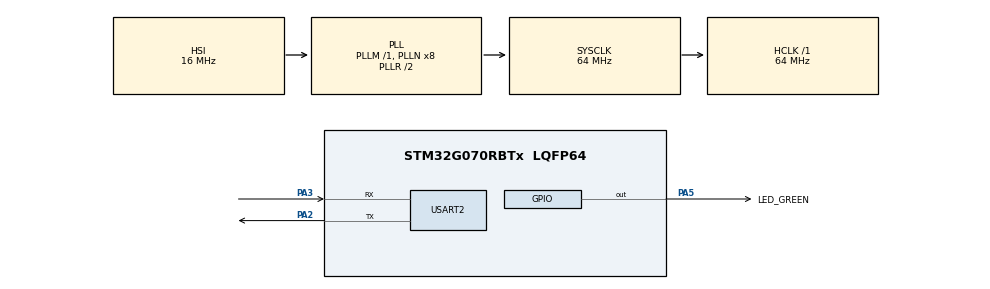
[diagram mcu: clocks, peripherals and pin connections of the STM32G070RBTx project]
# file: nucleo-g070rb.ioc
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Dma.Request0=USART2_TX
Dma.USART2_TX.0.Direction=DMA_MEMORY_TO_PERIPH
Dma.USART2_TX.0.EventEnable=DISABLE
Dma.USART2_TX.0.Instance=DMA1_Channel1
Dma.USART2_TX.0.MemDataAlignment=DMA_MDATAALIGN_BYTE
Dma.USART2_TX.0.MemInc=DMA_MINC_ENABLE
Dma.USART2_TX.0.Mode=DMA_NORMAL
Dma.USART2_TX.0.PeriphDataAlignment=DMA_PDATAALIGN_BYTE
Dma.USART2_TX.0.PeriphInc=DMA_PINC_DISABLE
Dma.USART2_TX.0.Polarity=HAL_DMAMUX_REQ_GEN_RISING
Dma.USART2_TX.0.Priority=DMA_PRIORITY_LOW
Dma.USART2_TX.0.RequestNumber=1
Dma.USART2_TX.0.SignalID=NONE
Dma.USART2_TX.0.SyncEnable=DISABLE
Dma.USART2_TX.0.SyncPolarity=HAL_DMAMUX_SYNC_NO_EVENT
Dma.USART2_TX.0.SyncRequestNumber=1
Dma.USART2_TX.0.SyncSignalID=NONE
FREERTOS.BinarySemaphores01=elog_lock,Dynamic,NULL;elog_async,Dynamic,NULL;elog_dma_lock,Dynamic,NULL
FREERTOS.Tasks01=defaultTask,24,256,StartDefaultTask,Default,NULL,Static,defaultTaskBuffer,defaultTaskControlBlock;elog,8,512,elog_entry,As external,NULL,Static,elogBuffer,elogControlBlock
FREERTOS.configUSE_NEWLIB_REENTRANT=1
Mcu.Family=STM32G0
Mcu.Name=STM32G070RBTx
Mcu.Package=LQFP64
NVIC.DMA1_Channel1_IRQn=true\:3\:0\:false\:false\:true\:true\:false\:true\:true
NVIC.TIM1_BRK_UP_TRG_COM_IRQn=true\:3\:0\:false\:false\:true\:false\:false\:true\:true
NVIC.TimeBase=TIM1_BRK_UP_TRG_COM_IRQn
NVIC.TimeBaseIP=TIM1
NVIC.USART2_IRQn=true\:3\:0\:false\:false\:true\:true\:true\:true\:true
PA13.GPIO_Label=TMS
PA13.Mode=Serial_Wire
PA13.Signal=SYS_SWDIO
PA14-BOOT0.GPIO_Label=TCK
PA14-BOOT0.Mode=Serial_Wire
PA14-BOOT0.Signal=SYS_SWCLK
PA2.GPIO_PuPd=GPIO_PULLUP
PA2.Mode=Asynchronous
PA2.Signal=USART2_TX
PA3.GPIO_PuPd=GPIO_PULLUP
PA3.Mode=Asynchronous
PA3.Signal=USART2_RX
PA5.GPIO_Label=LED_GREEN
PA5.GPIO_Speed=GPIO_SPEED_FREQ_HIGH
PA5.Signal=GPIO_Output
PC13.Mode=SYS_WakeUp1
PC13.Signal=SYS_WKUP2
PC14-OSC32_IN\ (PC14).Mode=LSE-External-Oscillator
PC14-OSC32_IN\ (PC14).Signal=RCC_OSC32_IN
PC15-OSC32_OUT\ (PC15).Mode=LSE-External-Oscillator
PC15-OSC32_OUT\ (PC15).Signal=RCC_OSC32_OUT
PF0-OSC_IN\ (PF0).GPIO_Label=MCO
PF0-OSC_IN\ (PF0).Mode=HSE-External-Clock-Source
PF0-OSC_IN\ (PF0).Signal=RCC_OSC_IN
ProjectManager.HeapSize=0x200
ProjectManager.StackSize=0x400
ProjectManager.TargetToolchain=STM32CubeIDE
RCC.ADCFreq_Value=64000000
RCC.AHBFreq_Value=64000000
RCC.CortexFreq_Value=64000000
RCC.EXTERNAL_CLOCK_VALUE=12288000
RCC.HCLKFreq_Value=64000000
RCC.HSE_VALUE=8000000
RCC.HSI_VALUE=16000000
RCC.SYSCLKFreq_VALUE=64000000
RCC.SYSCLKSource=RCC_SYSCLKSOURCE_PLLCLK
RCC.VCOOutputFreq_Value=128000000
USART2.VirtualMode-Asynchronous=VM_ASYNC
USART2.WordLength=WORDLENGTH_8B
VP_FREERTOS_VS_CMSIS_V2.Mode=CMSIS_V2
VP_SYS_VS_tim1.Mode=TIM1
board=NUCLEO-G070RB

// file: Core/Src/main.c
/* USER CODE BEGIN Header */
/**
  ******************************************************************************
  * @file           : main.c
  * @brief          : Main program body
  ******************************************************************************
  * @attention
  *
  * Copyright (c) 2022 STMicroelectronics.
  * All rights reserved.
  *
  * This software is licensed under terms that can be found in the LICENSE file
  * in the root directory of this software component.
  * If no LICENSE file comes with this software, it is provided AS-IS.
  *
  ******************************************************************************
  */
/* USER CODE END Header */
#include "main.h"
#include "cmsis_os.h"
#include "dma.h"
#include "usart.h"
#include "gpio.h"

/* USER CODE BEGIN Includes */
#include "elog.h"
/* USER CODE END Includes */

void SystemClock_Config(void);
void MX_FREERTOS_Init(void);

/* USER CODE BEGIN 0 */
void HAL_UART_TxCpltCallback(UART_HandleTypeDef *huart) {
    if (huart->Instance == huart2.Instance) {
        extern osSemaphoreId_t elog_dma_lockHandle;
        osSemaphoreRelease(elog_dma_lockHandle);
    }
}
/* USER CODE END 0 */

int main(void)
{

  /* MCU Configuration--------------------------------------------------------*/

  /* Reset of all peripherals, Initializes the Flash interface and the Systick. */
  HAL_Init();

  /* Configure the system clock */
  SystemClock_Config();

  /* Initialize all configured peripherals */
  MX_GPIO_Init();
  MX_DMA_Init();
  MX_USART2_UART_Init();
  /* USER CODE BEGIN 2 */
  elog_init();

  elog_set_fmt(ELOG_LVL_ASSERT, ELOG_FMT_ALL & ~ELOG_FMT_P_INFO);
  elog_set_fmt(ELOG_LVL_ERROR, ELOG_FMT_LVL | ELOG_FMT_TAG | ELOG_FMT_TIME);
  elog_set_fmt(ELOG_LVL_WARN, ELOG_FMT_LVL | ELOG_FMT_TAG | ELOG_FMT_TIME);
  elog_set_fmt(ELOG_LVL_INFO, ELOG_FMT_LVL | ELOG_FMT_TAG | ELOG_FMT_TIME);
  elog_set_fmt(ELOG_LVL_DEBUG, ELOG_FMT_ALL & ~(ELOG_FMT_FUNC | ELOG_FMT_P_INFO));
  elog_set_fmt(ELOG_LVL_VERBOSE, ELOG_FMT_ALL & ~(ELOG_FMT_FUNC | ELOG_FMT_P_INFO));

  elog_start();
  /* USER CODE END 2 */

  /* Init scheduler */
  osKernelInitialize();  /* Call init function for freertos objects (in freertos.c) */
  MX_FREERTOS_Init();

  /* Start scheduler */
  osKernelStart();

  /* We should never get here as control is now taken by the scheduler */
  /* Infinite loop */
  while (1)
  {

  }
}

void SystemClock_Config(void)
{
  RCC_OscInitTypeDef RCC_OscInitStruct = {0};
  RCC_ClkInitTypeDef RCC_ClkInitStruct = {0};

  /** Configure the main internal regulator output voltage
  */
  HAL_PWREx_ControlVoltageScaling(PWR_REGULATOR_VOLTAGE_SCALE1);

  /** Initializes the RCC Oscillators according to the specified parameters
  * in the RCC_OscInitTypeDef structure.
  */
  RCC_OscInitStruct.OscillatorType = RCC_OSCILLATORTYPE_HSI;
  RCC_OscInitStruct.HSIState = RCC_HSI_ON;
  RCC_OscInitStruct.HSIDiv = RCC_HSI_DIV1;
  RCC_OscInitStruct.HSICalibrationValue = RCC_HSICALIBRATION_DEFAULT;
  RCC_OscInitStruct.PLL.PLLState = RCC_PLL_ON;
  RCC_OscInitStruct.PLL.PLLSource = RCC_PLLSOURCE_HSI;
  RCC_OscInitStruct.PLL.PLLM = RCC_PLLM_DIV1;
  RCC_OscInitStruct.PLL.PLLN = 8;
  RCC_OscInitStruct.PLL.PLLP = RCC_PLLP_DIV2;
  RCC_OscInitStruct.PLL.PLLR = RCC_PLLR_DIV2;
  if (HAL_RCC_OscConfig(&RCC_OscInitStruct) != HAL_OK)
  {
    Error_Handler();
  }

  /** Initializes the CPU, AHB and APB buses clocks
  */
  RCC_ClkInitStruct.ClockType = RCC_CLOCKTYPE_HCLK|RCC_CLOCKTYPE_SYSCLK
                              |RCC_CLOCKTYPE_PCLK1;
  RCC_ClkInitStruct.SYSCLKSource = RCC_SYSCLKSOURCE_PLLCLK;
  RCC_ClkInitStruct.AHBCLKDivider = RCC_SYSCLK_DIV1;
  RCC_ClkInitStruct.APB1CLKDivider = RCC_HCLK_DIV1;

  if (HAL_RCC_ClockConfig(&RCC_ClkInitStruct, FLASH_LATENCY_2) != HAL_OK)
  {
    Error_Handler();
  }
}

void HAL_TIM_PeriodElapsedCallback(TIM_HandleTypeDef *htim)
{
  if (htim->Instance == TIM1) {
    HAL_IncTick();
  }
}

void Error_Handler(void)
{
  __disable_irq();
  while (1)
  {
  }
}

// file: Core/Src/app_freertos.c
/* USER CODE BEGIN Header */
/**
  ******************************************************************************
  * File Name          : app_freertos.c
  * Description        : Code for freertos applications
  ******************************************************************************
  * @attention
  *
  * Copyright (c) 2022 STMicroelectronics.
  * All rights reserved.
  *
  * This software is licensed under terms that can be found in the LICENSE file
  * in the root directory of this software component.
  * If no LICENSE file comes with this software, it is provided AS-IS.
  *
  ******************************************************************************
  */
/* USER CODE END Header */

#include "FreeRTOS.h"
#include "task.h"
#include "main.h"
#include "cmsis_os.h"

/* USER CODE BEGIN Includes */
#include "elog.h"
/* USER CODE END Includes */

typedef StaticTask_t osStaticThreadDef_t;

/* Definitions for defaultTask */
osThreadId_t defaultTaskHandle;
uint32_t defaultTaskBuffer[ 256 ];
osStaticThreadDef_t defaultTaskControlBlock;
const osThreadAttr_t defaultTask_attributes = {
  .name = "defaultTask",
  .stack_mem = &defaultTaskBuffer[0],
  .stack_size = sizeof(defaultTaskBuffer),
  .cb_mem = &defaultTaskControlBlock,
  .cb_size = sizeof(defaultTaskControlBlock),
  .priority = (osPriority_t) osPriorityNormal,
};
/* Definitions for elog */
osThreadId_t elogHandle;
uint32_t elogBuffer[ 512 ];
osStaticThreadDef_t elogControlBlock;
const osThreadAttr_t elog_attributes = {
  .name = "elog",
  .stack_mem = &elogBuffer[0],
  .stack_size = sizeof(elogBuffer),
  .cb_mem = &elogControlBlock,
  .cb_size = sizeof(elogControlBlock),
  .priority = (osPriority_t) osPriorityLow,
};
/* Definitions for elog_lock */
osSemaphoreId_t elog_lockHandle;
const osSemaphoreAttr_t elog_lock_attributes = {
  .name = "elog_lock"
};
/* Definitions for elog_async */
osSemaphoreId_t elog_asyncHandle;
const osSemaphoreAttr_t elog_async_attributes = {
  .name = "elog_async"
};
/* Definitions for elog_dma_lock */
osSemaphoreId_t elog_dma_lockHandle;
const osSemaphoreAttr_t elog_dma_lock_attributes = {
  .name = "elog_dma_lock"
};

void StartDefaultTask(void *argument);
extern void elog_entry(void *argument);

void MX_FREERTOS_Init(void); /* (MISRA C 2004 rule 8.1) */

void MX_FREERTOS_Init(void) {

  /* Create the semaphores(s) */
  /* creation of elog_lock */
  elog_lockHandle = osSemaphoreNew(1, 1, &elog_lock_attributes);

  /* creation of elog_async */
  elog_asyncHandle = osSemaphoreNew(1, 1, &elog_async_attributes);

  /* creation of elog_dma_lock */
  elog_dma_lockHandle = osSemaphoreNew(1, 1, &elog_dma_lock_attributes);

  /* Create the thread(s) */
  /* creation of defaultTask */
  defaultTaskHandle = osThreadNew(StartDefaultTask, NULL, &defaultTask_attributes);

  /* creation of elog */
  elogHandle = osThreadNew(elog_entry, NULL, &elog_attributes);

}

void StartDefaultTask(void *argument)
{
  /* USER CODE BEGIN StartDefaultTask */
  static const char* TAG = "main";
  /* Infinite loop */
  for(;;)
  {
    osDelay(1000);
	elog_i(TAG, "HelloWorld");
	elog_w(TAG, "HelloWorld");
	elog_e(TAG, "HelloWorld");
  }
  /* USER CODE END StartDefaultTask */
}
